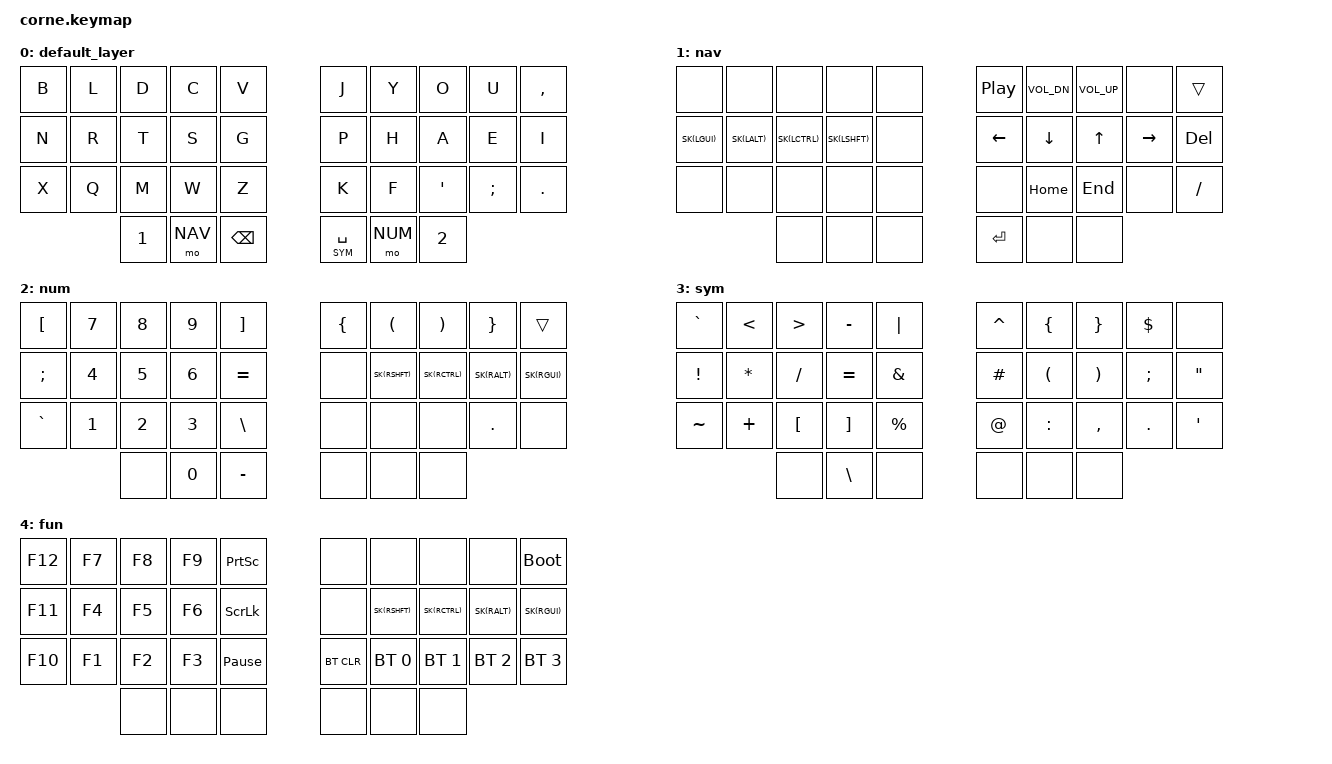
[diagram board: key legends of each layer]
#include <behaviors.dtsi>
#include <dt-bindings/zmk/keys.h>
#include <dt-bindings/zmk/bt.h>

#define             BASE    0
#define             NAV     1
#define             NUM     2
#define             SYM     3
#define             FUN     4

#define VOL_U       &kp C_VOL_UP
#define VOL_D       &kp C_VOL_DN
#define PB          &kp PAUSE_BREAK

#define BTCLR       &bt BT_CLR
#define BT0         &bt BT_SEL 0
#define BT1         &bt BT_SEL 1
#define BT2         &bt BT_SEL 2
#define BT3         &bt BT_SEL 3

#define SK(KEY)     &nk KEY KEY

&kscan0 {
    debounce-press-ms = <12>;
    debounce-release-ms = <12>;
};
&sk {
    release-after-ms = <2000>;
    ignore-modifiers;
};
&mt {
    tapping-term-ms = <200>; // This is the value already set by default
};

&caps_word {
    continue-list = <UNDERSCORE MINUS BACKSPACE>;
};

/ {
        combos {
            compatible = "zmk,combos";

            combo_esc {
                timeout-ms = <30>;
                key-positions = <11 12>;
                bindings = <&kp ESC>;
                layers = <NAV NUM>;
            };

            combo_esc_base {
                timeout-ms = <30>;
                key-positions = <12 22>;
                bindings = <&kp ESC>;
                layers = <BASE>;
            };

            combo_tab {
                timeout-ms = <30>;
                key-positions = <12 13>;
                bindings = <&kp TAB>;
                layers = <NUM>;
            };

            combo_tab_base {
                timeout-ms = <30>;
                key-positions = <13 23>;
                bindings = <&kp TAB>;
                layers = <BASE>;
            };

            combo_ret {
                timeout-ms = <30>;
                key-positions = <17 18>;
                bindings = <&kp RET>;
                layers = <BASE NAV NUM FUN>;
            };

            combo_ret_base {
                timeout-ms = <30>;
                key-positions = <16 26>;
                bindings = <&kp RET>;
                layers = <BASE>;
            };

            combo_caps_word {
                timeout-ms = <30>;
                key-positions = <4 14>;
                bindings = <&caps_word>;
                layers = <NUM>;
            };

            // layer combos
            combo_fun {
                timeout-ms = <30>;
                key-positions = <30 33>;
                bindings = <&mo FUN>;
                layers = <BASE>;
            };
            combo_sym {
                timeout-ms = <30>;
                key-positions = <31 32>;
                bindings = <&mo SYM>;
                layers = <BASE>;
            };
        };

        behaviors {

            // https://github.com/dxmh/zmk-config
            // Sticky key on tap, normal key on hold
            // Useful for modifier-clicking without the modifier remaining active
            nk: not_so_sticky_key {
                compatible = "zmk,behavior-hold-tap";
                label = "NOT_SO_STICKY_KEY";
                #binding-cells = <2>;
                tapping_term_ms = <200>;
                flavor = "balanced";
                bindings = <&kp>, <&sk>;
            };
        };
        chosen {
            zmk,matrix_transform = &five_column_transform;
        };
        keymap {
            compatible = "zmk,keymap";

            default_layer {
                bindings = <
                   &kp B       &kp L       &kp D       &kp C       &kp V       /**/ /**/       &kp J       &kp Y       &kp O       &kp U       &kp COMMA   
                    &kp N       &kp R       &kp T       &kp S       &kp G       /**/ /**/       &kp P       &kp H       &kp A       &kp E       &kp I      
                    &kp X       &kp Q       &kp M       &kp W       &kp Z       /**/ /**/       &kp K       &kp F       &kp SQT     &kp SEMI    &kp DOT    
                                            &kp N1            &mo NAV   &kp BSPC                &lt SYM SPC            &mo NUM    &kp N2    
                >;
                };

                nav {
                bindings = <
                    &none       &none       &none       &none       &none       /**/ /**/       &kp C_PP    VOL_D       VOL_U       &none       &trans     
                    SK(LGUI)    SK(LALT)    SK(LCTRL)   SK(LSHFT)   &none       /**/ /**/       &kp LEFT    &kp DOWN    &kp UP      &kp RIGHT   &kp DEL    
                    &none       &none       &none       &none       &none       /**/ /**/       &none       &kp HOME    &kp END     &none       &kp SLASH  
                                            &none       &none       &none                       &kp RET     &none       &none
                >;
                };
                num {
                bindings = <
                    &kp LBKT    &kp N7      &kp N8      &kp N9      &kp RBKT    /**/ /**/       &kp LBRC    &kp LPAR    &kp RPAR    &kp RBRC    &trans    
                    &kp SEMI    &kp N4      &kp N5      &kp N6      &kp EQUAL   /**/ /**/       &none       SK(RSHFT)   SK(RCTRL)   SK(RALT)    SK(RGUI)  
                    &kp GRAVE   &kp N1      &kp N2      &kp N3      &kp BSLH    /**/ /**/       &none       &none       &none       &kp DOT     &none      
                                            &none            &kp N0      &kp MINUS                   &none       &none &none
                >;
                };	                
                sym {
                bindings = <
                    &kp GRAVE  &kp LT    &kp GT     &kp MINUS   &kp PIPE   /**/ /**/   &kp CARET   &kp LBRC   &kp RBRC     &kp DOLLAR   &none  
                    &kp EXCL   &kp ASTRK &kp FSLH &kp EQUAL   &kp AMPS   /**/ /**/   &kp HASH    &kp LPAR   &kp RPAR     &kp SEMI     &kp DQT  
                    &kp TILDE  &kp PLUS  &kp LBKT   &kp RBKT    &kp PRCNT  /**/ /**/   &kp AT      &kp COLON  &kp COMMA &kp DOT       &kp SQT
                                         &none           &kp BSLH  &none                  &none       &none &none
                >;
                };	
                fun {
                bindings = <
                    &kp F12     &kp F7      &kp F8      &kp F9      &kp PSCRN   /**/ /**/       &none       &none       &none       &none       &bootloader 
                    &kp F11     &kp F4      &kp F5      &kp F6      &kp SLCK    /**/ /**/       &none       SK(RSHFT)   SK(RCTRL)   SK(RALT)    SK(RGUI)    
                    &kp F10     &kp F1      &kp F2      &kp F3      PB          /**/ /**/       BTCLR       BT0         BT1         BT2         BT3            
                                            &none            &none       &none                       &none       &none &none
                >;
                };	

         };
};
